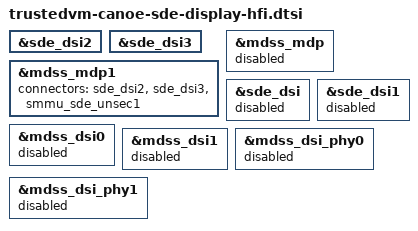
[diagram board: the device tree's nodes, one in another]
// SPDX-License-Identifier: BSD-3-Clause
/*
 * Copyright (c) Qualcomm Technologies, Inc. and/or its subsidiaries.
 */

#include "canoe-sde-display-common-hfi.dtsi"
#include <dt-bindings/interrupt-controller/arm-gic.h>
#include <dt-bindings/mailbox/qcom-ipcc-canoe.h>
#include <dt-bindings/mailbox/qcom-ipcc.h>

&sde_dsi2 {
	status = "ok";
};

&sde_dsi3 {
	 status = "ok";
};

&mdss_mdp1 {
	connectors = <&sde_dsi2 &sde_dsi3 &smmu_sde_unsec1>;
};

&mdss_mdp {
	status = "disabled";
};

&sde_dsi {
	status = "disabled";
};

&sde_dsi1 {
	status = "disabled";
};

&mdss_dsi0 {
	status = "disabled";
};

&mdss_dsi1 {
	status = "disabled";
};

&mdss_dsi_phy0 {
	status = "disabled";
};

&mdss_dsi_phy1 {
	status = "disabled";
};

